# DEVICE_PRM register map
Vendor: Texas Instruments
Peripheral module from a debugger description file (folder omap4460).
Registers are 32-bit, access per field, reset 0x0 unless marked. A register's access mark holds for its fields unless they carry their own. Offsets are as the file gives them; lines under a group give offsets from that group; [hi:lo] are bit positions; {n}, {i} and the like mark numbered series; 'fields as' and 'values as' point back to an identical list; <NAME> marks a mode.

## DEVICE_PRM
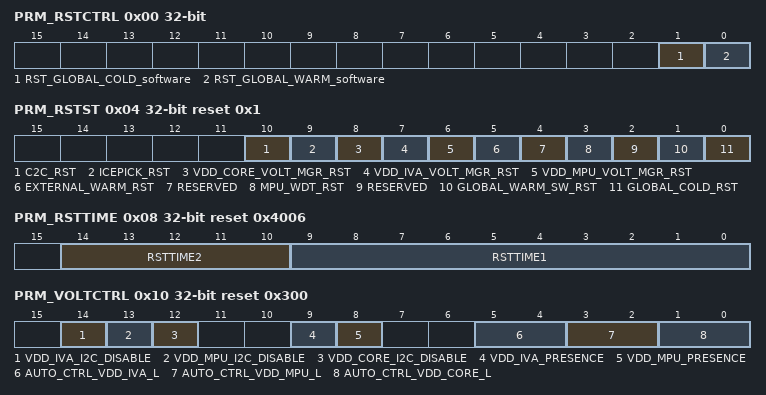
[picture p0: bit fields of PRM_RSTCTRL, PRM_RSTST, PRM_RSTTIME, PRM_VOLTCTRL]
0x00 PRM_RSTCTRL — Global software cold and warm reset control. This register is auto-cleared. Only write 1 is possible. A read returns 0 only.
  [1] RST_GLOBAL_COLD_software rw — Global COLD software reset control. This bit is reset only upon a global cold source of reset.
    0=Global COLD software reset is cleared; 1=Triggers a global COLD software reset. The software must ensure the SDRAM is properly put in sef-refresh mode before applying this reset.
  [0] RST_GLOBAL_WARM_software rw — Global WARM software reset control. This bit is reset upon any global source of reset (warm and cold).
    0=Global warm software reset is cleared; 1=Triggers a global warm software reset
0x04 PRM_RSTST access not given reset 0x1 — This register logs the global reset sources. Each bit is set upon release of the domain reset signal. Must be cleared by software. [warm reset insensitive]
  [10] C2C_RST — C2C warm reset event. This is a source of global warm reset. (access RW W1toClr)
    0=No C2C warm reset; 1=C2C warm reset has occurred
  [9] ICEPICK_RST — IcePick reset event. This is a source of global warm reset initiated by the emulation. (access RW W1toClr)
    0=No ICEPICK reset; 1=IcePick reset has occurred
  [8] VDD_CORE_VOLT_MGR_RST — VDD_CORE voltage manager reset event This is a source of global WARM reset. (access RW W1toClr)
    0=No VDD_CORE voltage manager reset; 1=VDD_CORE voltage manager reset has occurred
  [7] VDD_IVA_VOLT_MGR_RST — VDD_IVA voltage manager reset event This is a source of global WARM reset. (access RW W1toClr)
    0=No VDD_IVA voltage manager reset; 1=VDD_IVA voltage manager reset has occurred
  [6] VDD_MPU_VOLT_MGR_RST — VDD_MPU voltage manager reset event This is a source of global WARM reset. (access RW W1toClr)
    0=No VDD_MPU voltage manager reset; 1=VDD_MPU voltage manager reset has occurred
  [5] EXTERNAL_WARM_RST — External warm reset event (access RW W1toClr)
    0=No global warm reset; 1=Global external warm reset has occurred
  [4] RESERVED — (access RW W1toClr)
  [3] MPU_WDT_RST — MPU Watchdog timer reset event. This is a source of global WARM reset. (access RW W1toClr)
    0=No MPU watchdog reset; 1=MPU wachtdog reset has occurred
  [2] RESERVED — (access RW W1toClr)
  [1] GLOBAL_WARM_SW_RST — Global warm software reset event (access RW W1toClr)
    0=No global warm software reset; 1=Global warm software reset has occurred
  [0] GLOBAL_COLD_RST — Power-on (cold) reset event (access RW W1toClr)
    0=No power-on reset; 1=Power-on reset has occurred
0x08 PRM_RSTTIME reset 0x4006 — Reset duration control. [warm reset insensitive]
  [14:10] RSTTIME2 rw — (Power domain) reset duration 2 (number of RM.SYSCLK clock cycles)
  [9:0] RSTTIME1 rw — (Global) reset duration 1 (number of Func_32k.clk clock cycles)
0x0C PRM_CLKREQCTRL — This register allows controlling the CLKREQ signal towards SCRM.
  [2:0] CLKREQ_COND rw — Control upon which condition CLKREQ signal is de-asserted.
    0=CLKREQ is never de-asserted; 1=CLKREQ is de-asserted when system clock is not required by any function in the device and if all voltage domains are in OFF state; 2=CLKREQ is de-asserted when system clock is not required by any function in the device and if all voltage domains are in RET or OFF state; 3=CLKREQ is de-asserted when system clock is not required by any function in the device and if all voltage domains are in SLEEP or RET or OFF state; 4=CLKREQ is de-asserted when system clock is not required by any function in the device. This is designed for low-power use-cases using the DPLL cascading scheme (ex: MP3); 5=CLKREQ_COND_5_r (Reserved); 6=CLKREQ_COND_6_r (Reserved); 7=CLKREQ_COND_7_r (Reserved)
0x10 PRM_VOLTCTRL reset 0x300 — This register provides voltage domain management controls.
  [14] VDD_IVA_I2C_DISABLE rw — This bit allows disabling I2C interface with powerIC for IVA voltage (for debug purpose only). [warm reset insensitive]
    0=Normal mode: I2C is enabled; 1=Debug mode: I2C is disabled
  [13] VDD_MPU_I2C_DISABLE rw — This bit allows disabling I2C interface with powerIC for MPU voltage (for debug purpose only). [warm reset insensitive]
    0=Normal mode: I2C is enabled; 1=Debug mode: I2C is disabled
  [12] VDD_CORE_I2C_DISABLE rw — This bit allows disabling I2C interface with powerIC for CORE voltage (for debug purpose only). [warm reset insensitive]
    0=Normal mode: I2C is enabled; 1=Debug mode: I2C is disabled
  [9] VDD_IVA_PRESENCE rw — This bit control the presence of IVA voltage in device. [warm reset insensitive]
    0=IVA voltage is not present as an individual voltage: IVA voltage is merged with MPU voltage if VDD_MPU_presence=1. IVA voltage is merged with CORE voltage if VDD_MPU_presence=0.; 1=IVA voltage is present on the device
  [8] VDD_MPU_PRESENCE rw — This bit control the presence of MPU voltage in device. [warm reset insensitive]
    0=MPU voltage is not present as an individual voltage: MPU voltage is merged with IVA voltage if VDD_IVA_presence=1. MPU voltage is merged with CORE voltage if VDD_IVA_presence=0.; 1=MPU voltage is present on the device
  [5:4] AUTO_CTRL_VDD_IVA_L rw — This bit field specifies the state to which the hardware can automatically transition the VDD_IVA_L voltage domain.
    0=Voltage domain transitions are disabled; 1=Voltage domain transitions to SLEEP are enabled; 2=Voltage domain transitions to RET are enabled; 3=AUTO_CTRL_VDD_IVA_L_3_r (reserved)
  [3:2] AUTO_CTRL_VDD_MPU_L rw — This bit field specifies the state to which the hardware can automatically transition the VDD_MPU_L voltage domain.
    0=Voltage domain transitions are disabled; 1=Voltage domain transitions to SLEEP are enabled; 2=Voltage domain transitions to RET are enabled; 3=AUTO_CTRL_VDD_MPU_L_3_r (reserved)
  [1:0] AUTO_CTRL_VDD_CORE_L rw — This bit field specifies the state to which the hardware can automatically transition the VDD_CORE_L voltage domain.
    0=Voltage domain transitions are disabled; 1=Voltage domain transitions to SLEEP are enabled; 2=Voltage domain transitions to RET are enabled; 3=AUTO_CTRL_VDD_CORE_L_3_r (reserved)
0x14 PRM_PWRREQCTRL — This register allows controlling the signal towards power IC.
  [1:0] PWRREQ_COND rw — Control upon which condition from MPU, IVA and CORE voltage domainsPWRREQ is de-asserted.
    0=is never de-asserted; 1=is de-asserted if all voltage domain are in SLEEP, RET or OFF state. Conversely, is asserted upon any voltage domain entering or staying in ON state.; 2=is de-asserted if all voltage domain are in RET or OFF state. Conversely, is asserted upon any voltage domain entering or staying in ON or SLEEP state.; 3=is de-asserted if all voltage domain are in OFF state. Conversely, is asserted upon any voltage domain entering or staying in ON or SLEEP or RET state.
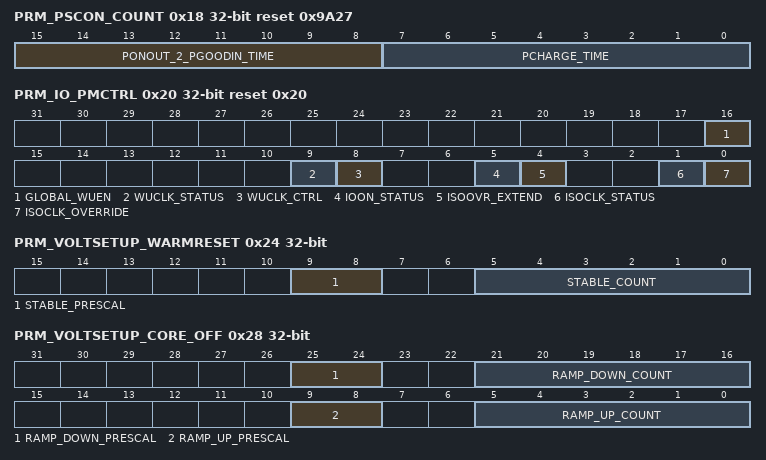
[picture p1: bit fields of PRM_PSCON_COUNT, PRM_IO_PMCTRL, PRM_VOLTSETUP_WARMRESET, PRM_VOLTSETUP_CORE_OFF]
0x18 PRM_PSCON_COUNT reset 0x9A27 — This register allows controlling 2 parameters for power state controller. [warm reset insensitive]
  [15:8] PONOUT_2_PGOODIN_TIME rw — The value 'NbCycles' set in this field determines the duration of the PONOUT to PGOODIN transition for power domain without DPS. The duration is computed as 8 x NbCycles of system clock cycles.
  [7:0] PCHARGE_TIME rw — Number of system clock cycles for the SRAM precharge duration.
0x1C PRM_IO_COUNT reset 0x3A — This register allows controlling LPDDR2 I/O isolation removal setup. [warm reset insensitive]
  [7:0] ISO_2_ON_TIME rw — Determines the setup time of the LPDDR2 IOs going out of isolation. Counting on the system clock. Target is 1.5us.
0x20 PRM_IO_PMCTRL reset 0x20 — This register allows overriding ISOCLK signal towards I/O pad ring.
  [16] GLOBAL_WUEN rw — Global I/O wakeup enable. This is a gating condition to all individual I/O WUEN coming from control module. Gating is done in the Spinner logic.
    0=All individual I/O WUEN are gated in the Spinner logic (overriden to 0); 1=All individual I/O WUEN from control module are going to IOs
  [9] WUCLK_STATUS ro — Gives value of WUCLKOUT signal coming back from I/O pad ring.
  [8] WUCLK_CTRL rw — Direct control on WUCLKIN signal to I/O pad ring.
    0=WUCLKIN signal is driven to 0. I/O wakeup daisy chain is functional as well as I/O whose wakeup feature is enabled.; 1=WUCLKIN signal is driven to 1. I/O wakeup daisy chain is reset and is latching current pad states and WUEN inputs.
  [5] IOON_STATUS ro — Gives the functional status of the I/O ring.
    0=IOON_STATUS_0_r (Part or all of the IOs are not in the ON state, that is are in isolation state); 1=IOON_STATUS_1_r (All IOs are in the ON state)
  [4] ISOOVR_EXTEND rw — Control non-EMIF I/O isolation extension upon a device wakeup from OFF mode.
    0=Non-EMIF I/O isolation is not extended. 'EMIF_ON' I/O transition happens as soon as automatic restore is completed; 1=Non-EMIF I/O isolation is extended. 'EMIF_ON' I/O transition is stalled
  [1] ISOCLK_STATUS ro — Gives value of ISOCLKOUT signal coming back from I/O pad ring.
  [0] ISOCLK_OVERRIDE rw — Override control on ISOCLKIN signal to I/O pad ring. Override should be used at boot time only when it is needed to change the mode of an I/O from 1.8-V default mode to 1.2-V mode. When not overriden, this signal is controlled by hardware only.
    0=ISOCLKIN signal is not overriden; 1=ISOCLKIN signal is overriden to active value (1)
0x24 PRM_VOLTSETUP_WARMRESET — This register provides bit fields for specifying voltage ramp-up and ramp-down times for PRM managed external regulators. These values are used for VDD_CORE_L domain transitions with OFF state. [warm reset insensitive]
  [9:8] STABLE_PRESCAL rw — Determines prescaler for stabilization duration counting.
    0=Ramp-up counter is incremented every 32 system clock cycles; 1=Ramp-up counter is incremented every 256 system clock cycles; 2=Ramp-up counter is incremented every 2048 system clock cycles; 3=Ramp-up counter is incremented every 16384 system clock cycles
  [5:0] STABLE_COUNT rw — Determines the stabilization duration of all VDD_xxx_L regulators upon a global warm reset assertion. The duration is computed according to Stable_Prescal.
0x28 PRM_VOLTSETUP_CORE_OFF — This register provides bit fields for specifying voltage ramp-up and ramp-down times for PRM managed external regulators. These values are used for VDD_CORE_L domain transitions with OFF state. [warm reset insensitive]
  [25:24] RAMP_DOWN_PRESCAL rw — Determines prescaler for ramp-down duration counting.
    0=Ramp-down counter is incremented every 64 system clock cycles; 1=Ramp-down counter is incremented every 256 system clock cycles; 2=Ramp-down counter is incremented every 512 system clock cycles; 3=Ramp-down counter is incremented every 2048 system clock cycles
  [21:16] RAMP_DOWN_COUNT rw — Determines the ramp-down duration of VDD_CORE_L regulators. The duration is computed according to Ramp_Down_Prescal.
  [9:8] RAMP_UP_PRESCAL rw — Determines prescaler for ramp-up duration counting.
    0=Ramp-up counter is incremented every 64 system clock cycles; 1=Ramp-up counter is incremented every 256 system clock cycles; 2=Ramp-up counter is incremented every 512 system clock cycles; 3=Ramp-up counter is incremented every 2048 system clock cycles
  [5:0] RAMP_UP_COUNT rw — Determines the ramp-up duration of VDD_CORE_L regulators. The duration is computed according to Ramp_Up_Prescal. At cold reset, PRCM assumes that VDD_CORE_L will be at a valid ON voltage before SYS_NRESPWRON is de-asserted.
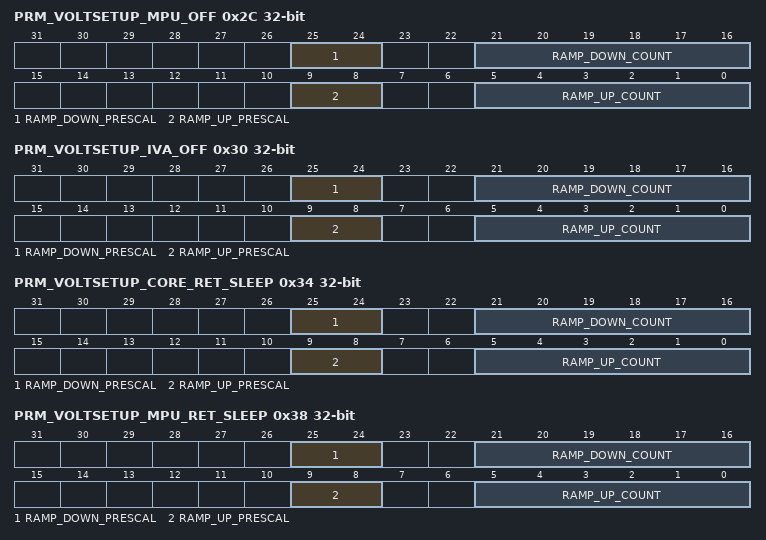
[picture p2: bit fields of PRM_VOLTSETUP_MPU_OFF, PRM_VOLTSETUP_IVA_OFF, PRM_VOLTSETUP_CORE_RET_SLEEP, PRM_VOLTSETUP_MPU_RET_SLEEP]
0x2C PRM_VOLTSETUP_MPU_OFF — This register provides bit fields for specifying voltage ramp-up and ramp-down times for PRM managed external regulators. These values are used for VDD_MPU_L domain transitions to or from OFF state. [warm reset insensitive]
  [25:24] RAMP_DOWN_PRESCAL rw — Determines prescaler for ramp-down duration counting.
    values as PRM_VOLTSETUP_CORE_OFF.RAMP_DOWN_PRESCAL
  [21:16] RAMP_DOWN_COUNT rw — Determines the ramp-down duration of VDD_MPU_L regulators. The duration is computed according to Ramp_Down_Prescal.
  [9:8] RAMP_UP_PRESCAL rw — Determines prescaler for ramp-up duration counting.
    values as PRM_VOLTSETUP_CORE_OFF.RAMP_UP_PRESCAL
  [5:0] RAMP_UP_COUNT rw — Determines the ramp-up duration of VDD_MPU_L regulators. The duration is computed according to Ramp_Up_Prescal. At cold reset, PRCM assumes that VDD_MPU_L will be at a valid ON voltage before SYS_NRESPWRON is de-asserted.
0x30 PRM_VOLTSETUP_IVA_OFF — This register provides bit fields for specifying voltage ramp-up and ramp-down times for PRM managed external regulators. These values are used for VDD_IVA_L domain transitions to or from OFF state. [warm reset insensitive]
  [25:24] RAMP_DOWN_PRESCAL rw — Determines prescaler for ramp-down duration counting.
    values as PRM_VOLTSETUP_CORE_OFF.RAMP_DOWN_PRESCAL
  [21:16] RAMP_DOWN_COUNT rw — Determines the ramp-down duration of VDD_IVA_L regulators. The duration is computed according to Ramp_Down_Prescal.
  [9:8] RAMP_UP_PRESCAL rw — Determines prescaler for ramp-up duration counting.
    values as PRM_VOLTSETUP_CORE_OFF.RAMP_UP_PRESCAL
  [5:0] RAMP_UP_COUNT rw — Determines the ramp-up duration of VDD_IVA_L regulators. The duration is computed according to Ramp_Up_Prescal. At cold reset, PRCM assumes that VDD_IVA_L will be at a valid ON voltage before SYS_NRESPWRON is de-asserted.
0x34 PRM_VOLTSETUP_CORE_RET_SLEEP — This register provides bit fields for specifying voltage ramp-up and ramp-down times for PRM managed external regulators. These values are used for VDD_CORE_L domain transitions between ON and RET or SLEEP state. [warm reset insensitive]
  [25:24] RAMP_DOWN_PRESCAL rw — Determines prescaler for ramp-down duration counting.
    values as PRM_VOLTSETUP_CORE_OFF.RAMP_DOWN_PRESCAL
  [21:16] RAMP_DOWN_COUNT rw — Determines the ramp-down duration of VDD_CORE_L regulators. The duration is computed according to Ramp_Down_Prescal.
  [9:8] RAMP_UP_PRESCAL rw — Determines prescaler for ramp-up duration counting.
    values as PRM_VOLTSETUP_CORE_OFF.RAMP_UP_PRESCAL
  [5:0] RAMP_UP_COUNT rw — Determines the ramp-up duration of VDD_CORE_L regulators. The duration is computed according to Ramp_Up_Prescal.
0x38 PRM_VOLTSETUP_MPU_RET_SLEEP — This register provides bit fields for specifying voltage ramp-up and ramp-down times for PRM managed external regulators. These values are used for VDD_MPU_L domain transitions between ON and RET or SLEEP state. [warm reset insensitive]
  [25:24] RAMP_DOWN_PRESCAL rw — Determines prescaler for ramp-down duration counting.
    values as PRM_VOLTSETUP_CORE_OFF.RAMP_DOWN_PRESCAL
  [21:16] RAMP_DOWN_COUNT rw — Determines the ramp-down duration of VDD_MPU_L regulators. The duration is computed according to Ramp_Down_Prescal.
  [9:8] RAMP_UP_PRESCAL rw — Determines prescaler for ramp-up duration counting.
    0=Ramp-up counter is incremented every 64 system clock cycles; 1=Ramp-up counter is incremented every256 system clock cycles; 2=Ramp-up counter is incremented every 512 system clock cycles; 3=Ramp-up counter is incremented every 2048 system clock cycles
  [5:0] RAMP_UP_COUNT rw — Determines the ramp-up duration of VDD_MPU_L regulators. The duration is computed according to Ramp_Up_Prescal.
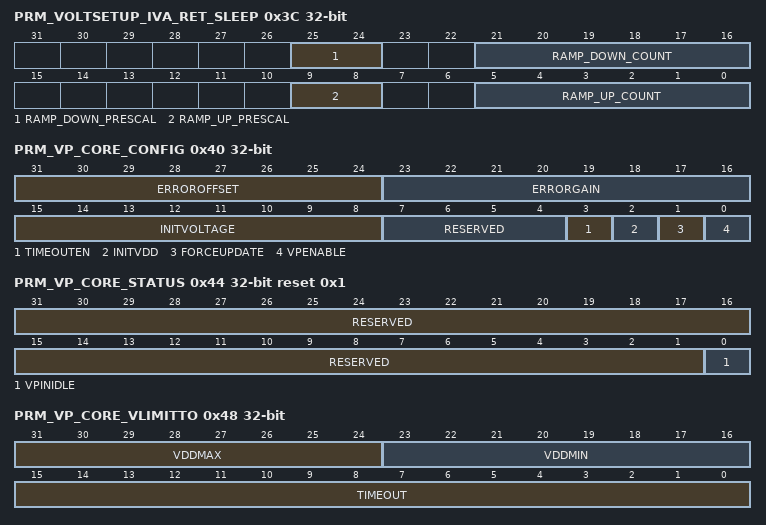
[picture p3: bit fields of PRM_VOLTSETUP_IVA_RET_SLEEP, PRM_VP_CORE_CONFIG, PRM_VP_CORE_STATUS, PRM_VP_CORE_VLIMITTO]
0x3C PRM_VOLTSETUP_IVA_RET_SLEEP — This register provides bit fields for specifying voltage ramp-up and ramp-down times for PRM managed external regulators. These values are used for VDD_IVA_L domain transitions between ON and RET or SLEEP state. [warm reset insensitive]
  [25:24] RAMP_DOWN_PRESCAL rw — Determines prescaler for ramp-down duration counting.
    values as PRM_VOLTSETUP_CORE_OFF.RAMP_DOWN_PRESCAL
  [21:16] RAMP_DOWN_COUNT rw — Determines the ramp-down duration of VDD_IVA_L regulators. The duration is computed according to Ramp_Down_Prescal.
  [9:8] RAMP_UP_PRESCAL rw — Determines prescaler for ramp-up duration counting.
    values as PRM_VOLTSETUP_CORE_OFF.RAMP_UP_PRESCAL
  [5:0] RAMP_UP_COUNT rw — Determines the ramp-up duration of VDD_IVA_L regulators. The duration is computed according to Ramp_Up_Prescal.
0x40 PRM_VP_CORE_CONFIG — This register allows the configuration of the Voltage Processor dedicated to CORE Voltage Domain (VDD_CORE_L).
  [31:24] ERROROFFSET rw — Offset value in the Error to Voltage converter (two's complement number).
  [23:16] ERRORGAIN rw — Gain value in the Error to Voltage converter (two's complement number).
  [15:8] INITVOLTAGE rw — Set the initial voltage level of the SMPS. It must be reconfigured before enable the SmartReflex around a new OPP.
  [7:4] RESERVED ro — Write 0's for future compatibility. Read is undefined.
  [3] TIMEOUTEN rw — Enable or disable the timeout capability of the Voltage Controller State Machine.
    0=Timeout is disabled. Loop will wait indefinitely.; 1=Timeout will occur when TIMEOUT cycles have elapsed
  [2] INITVDD rw — Initializes the voltage in the Voltage Processor.
    0=Reset the initialization bit; 1=The positive edge of InitVdd triggers a write of the value in the InitVoltage into the Voltage Processor
  [1] FORCEUPDATE rw — Forces an update of the SMPS.
    0=Reset the force bit; 1=The positive edge of ForceUpdate triggers an update of the voltage to the SMPS
  [0] VPENABLE rw — Enables or disables the Voltage Processor updates on SR_SInterruptz.
    0=Disables the Voltage Processor; 1=Enables the Voltage Processor
0x44 PRM_VP_CORE_STATUS ro reset 0x1 — This register reflects the idle state of the Voltage Processor dedicated to the CORE Voltage Domain (VDD_CORE_L. This register is read only and automatically updated.
  [31:1] RESERVED — Write 0's for future compatibility. Read is undefined.
  [0] VPINIDLE — CORE Voltage Processor idle status.
    0=VPINIDLE_0_r (The Voltage Processor for CORE is processing. Warm reset sensitive); 1=VPINIDLE_1_r (The Voltage Processor for CORE is in idle state.)
0x48 PRM_VP_CORE_VLIMITTO rw — This register allows the configuration of the voltage limits and timeout values of the Voltage Processor dedicated to the CORE Voltage Domain (VDD_CORE_L).
  [31:24] VDDMAX — Defines the maximum voltage supply level.
  [23:16] VDDMIN — Defines the minimum voltage supply level.
  [15:0] TIMEOUT — Defines Voltage Controller maximum wait time for responses, measured in sysclk cycles.
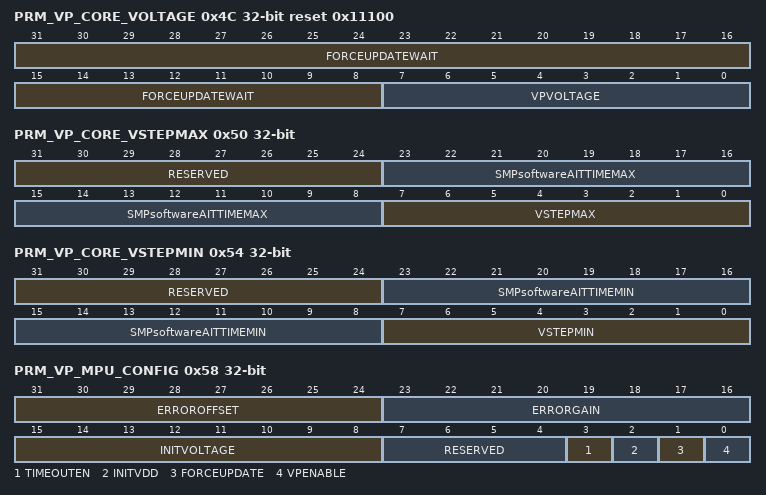
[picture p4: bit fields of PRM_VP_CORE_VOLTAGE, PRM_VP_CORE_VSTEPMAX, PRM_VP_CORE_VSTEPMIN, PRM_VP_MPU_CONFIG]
0x4C PRM_VP_CORE_VOLTAGE reset 0x11100 — This register indicates the current value of the SMPS voltage for the Voltage Processor dedicated to the CORE Voltage Domain (VDD_CORE_L).
  [31:8] FORCEUPDATEWAIT rw — The time voltage processor needs to wait for SMPS to be settled after receiving SMPS acknowledge. This wait only be used during force_update operation.
  [7:0] VPVOLTAGE ro — Indicates the current SMPS programmed voltage.
0x50 PRM_VP_CORE_VSTEPMAX — This register allows the programming of the maximum voltage step and waiting time of the Voltage Processor dedicated to CORE Voltage Domain (VDD_CORE_L).
  [31:24] RESERVED ro — Write 0's for future compatibility. Read is undefined.
  [23:8] SMPsoftwareAITTIMEMAX rw — Slew rate for positive voltage step (in number of cycles per step).
  [7:0] VSTEPMAX rw — Maximum voltage step
0x54 PRM_VP_CORE_VSTEPMIN — This register allows the programming of the minimum voltage step and waiting time of the Voltage Processor dedicated to the CORE Voltage Domain (VDD_CORE_L).
  [31:24] RESERVED ro — Write 0's for future compatibility. Read is undefined.
  [23:8] SMPsoftwareAITTIMEMIN rw — Slew rate for negative voltage step (in number of cycles per step).
  [7:0] VSTEPMIN rw — Minimum voltage step
0x58 PRM_VP_MPU_CONFIG — This register allows the configuration of the Voltage Processor dedicated to MPU Voltage Domain (VDD_MPU_L).
  fields as PRM_VP_CORE_CONFIG
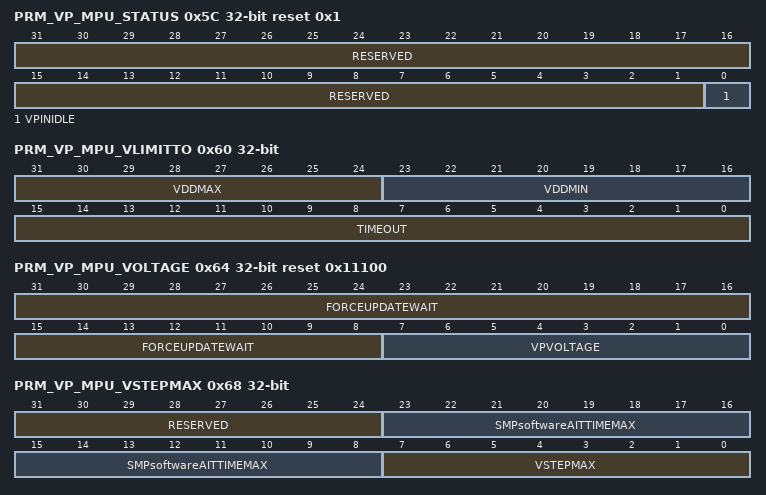
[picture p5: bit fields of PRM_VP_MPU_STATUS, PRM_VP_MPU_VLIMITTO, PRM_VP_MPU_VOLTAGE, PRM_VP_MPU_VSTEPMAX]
0x5C PRM_VP_MPU_STATUS ro reset 0x1 — This register reflects the idle state of the Voltage Processor dedicated to the MPU Voltage Domain (VDD_MPU_L. This register is read only and automatically updated.
  [31:1] RESERVED — Write 0's for future compatibility. Read is undefined.
  [0] VPINIDLE — Voltage Processor 1 idle status.
    0=VPINIDLE_0_r (The Voltage Processor 1 is processing.); 1=VPINIDLE_1_r (The Voltage Processor 1 is in idle state.)
0x60 PRM_VP_MPU_VLIMITTO rw — This register allows the configuration of the voltage limits and timeout values of the Voltage Processor dedicated to the MPU Voltage Domain (VDD_MPU_L).
  fields as PRM_VP_CORE_VLIMITTO
0x64 PRM_VP_MPU_VOLTAGE reset 0x11100 — This register indicates the current value of the SMPS voltage for the Voltage Processor dedicated to the MPU Voltage Domain (VDD_MPU_L).
  fields as PRM_VP_CORE_VOLTAGE
0x68 PRM_VP_MPU_VSTEPMAX — This register allows the programming of the maximum voltage step and waiting time of the Voltage Processor dedicated to MPU Voltage Domain (VDD_MPU_L).
  fields as PRM_VP_CORE_VSTEPMAX
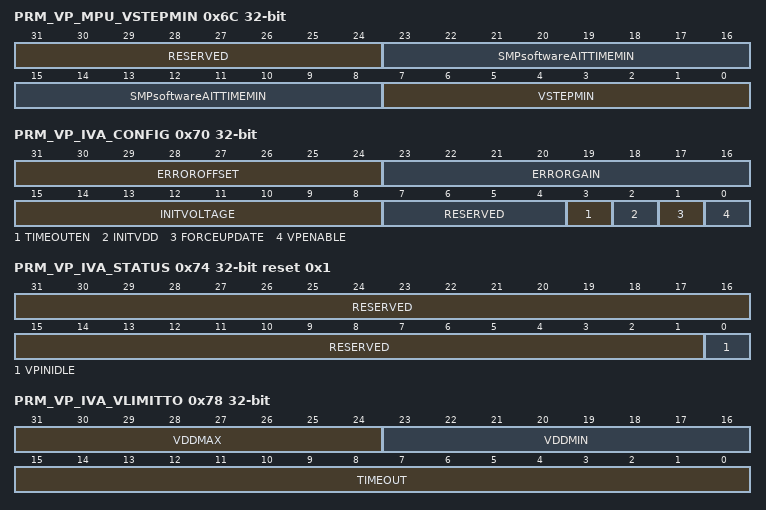
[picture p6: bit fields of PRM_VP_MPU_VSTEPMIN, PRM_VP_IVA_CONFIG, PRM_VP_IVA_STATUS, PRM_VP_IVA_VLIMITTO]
0x6C PRM_VP_MPU_VSTEPMIN — This register allows the programming of the minimum voltage step and waiting time of the Voltage Processor dedicated to the MPU Voltage Domain (VDD_MPU_L).
  fields as PRM_VP_CORE_VSTEPMIN
0x70 PRM_VP_IVA_CONFIG — This register allows the configuration of the Voltage Processor dedicated to IVAVoltage Domain (VDD_IVA_L).
  fields as PRM_VP_CORE_CONFIG
0x74 PRM_VP_IVA_STATUS ro reset 0x1 — This register reflects the idle state of the Voltage Processor dedicated to the MPU Voltage Domain (VDD_IVA_L. This register is read only and automatically updated.
  fields as PRM_VP_MPU_STATUS
0x78 PRM_VP_IVA_VLIMITTO rw — This register allows the configuration of the voltage limits and timeout values of the Voltage Processor dedicated to the IVA Voltage Domain (VDD_IVA_L).
  fields as PRM_VP_CORE_VLIMITTO
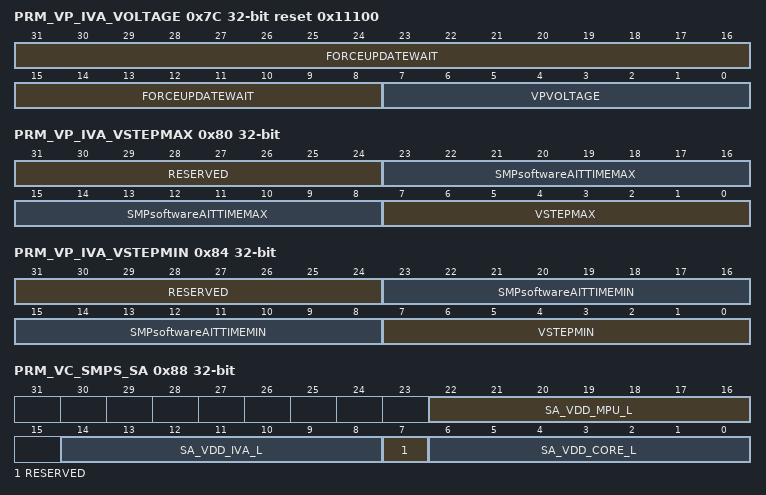
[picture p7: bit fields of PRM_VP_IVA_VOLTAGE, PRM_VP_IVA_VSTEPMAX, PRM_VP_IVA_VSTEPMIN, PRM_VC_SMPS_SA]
0x7C PRM_VP_IVA_VOLTAGE reset 0x11100 — This register indicates the current value of the SMPS voltage for the Voltage Processor dedicated to the IVA Voltage Domain (VDD_IVA_L).
  fields as PRM_VP_CORE_VOLTAGE
0x80 PRM_VP_IVA_VSTEPMAX — This register allows the programming of the maximum voltage step and waiting time of the Voltage Processor dedicated to IVA Voltage Domain (VDD_IVA_L).
  fields as PRM_VP_CORE_VSTEPMAX
0x84 PRM_VP_IVA_VSTEPMIN — This register allows the programming of the minimum voltage step and waiting time of the Voltage Processor dedicated to the IVA Voltage Domain (VDD_IVA_L).
  fields as PRM_VP_CORE_VSTEPMIN
0x88 PRM_VC_SMPS_SA — This register allows the setting of the I2C slave address of the Power IC device. [warm reset insensitive]
  [22:16] SA_VDD_MPU_L rw — Set the I2C slave address value for the third (if any) Power IC device.
  [14:8] SA_VDD_IVA_L rw — Set the I2C slave address value for the second (if any) Power IC device.
  [7] RESERVED ro — Write 0's for future compatibility. Read is undefined.
  [6:0] SA_VDD_CORE_L rw — Set the I2C slave address value for the first Power IC device.
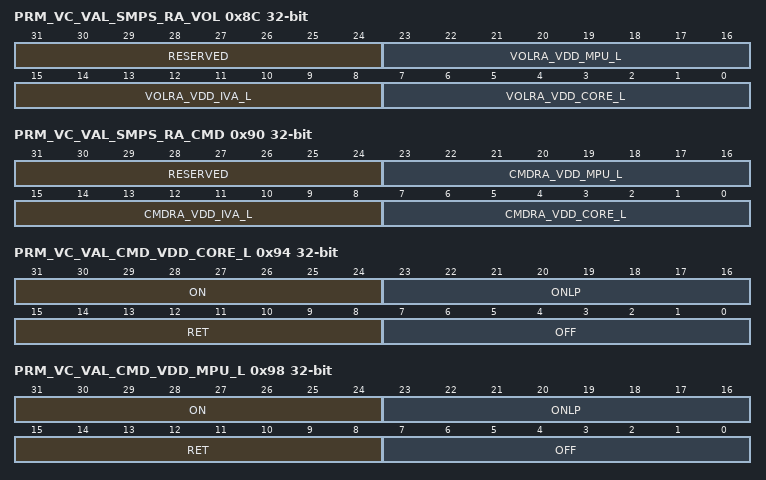
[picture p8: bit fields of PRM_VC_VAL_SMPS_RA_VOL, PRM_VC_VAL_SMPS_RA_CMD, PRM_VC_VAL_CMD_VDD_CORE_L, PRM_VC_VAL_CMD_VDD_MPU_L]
0x8C PRM_VC_VAL_SMPS_RA_VOL — This register allows the setting of the voltage configuration register address for the VDD channels. [warm reset insensitive]
  [31:24] RESERVED ro — Write 0's for future compatibility. Read is undefined.
  [23:16] VOLRA_VDD_MPU_L rw — Voltage configuration register address value for VDD_MPU_L channel
  [15:8] VOLRA_VDD_IVA_L rw — Voltage configuration register address value for VDD_IVA_L channel (if VDD_IVA_L source is placed in same chip as VDD_MPU_L source and have different voltage configuration register)
  [7:0] VOLRA_VDD_CORE_L rw — Voltage configuration register address value for the VDD_CORE_L channel (if VDD_CORE_L source is placed in same chip as VDD_MPU_L source and has different voltage configuration register)
0x90 PRM_VC_VAL_SMPS_RA_CMD — Command (ON/ON-Low-Power/Retention/OFF) configuration register address values for the VDD channels (if used SMPS chips have different command configuration register than voltage configuration register) [warm reset insensitive]
  [31:24] RESERVED ro — Write 0's for future compatibility. Read is undefined.
  [23:16] CMDRA_VDD_MPU_L rw — Command (ON/ON-Low-Power /Retention/OFF) configuration register address value for VDD_MPU_L channel
  [15:8] CMDRA_VDD_IVA_L rw — Command (ON/ON-Low-Power /Retention/OFF) configuration register address value for VDD_IVA_L channel (if VDD_IVA_L source has different command configuration register than voltage VDD_MPU_L)
  [7:0] CMDRA_VDD_CORE_L rw — Command (ON/ON-Low-Power /Retention/OFF) configuration register address value for VDD_CORE_L channel (if VDD_CORE_L source has different command configuration register than voltage VDD_MPU_L)
0x94 PRM_VC_VAL_CMD_VDD_CORE_L rw — This register allows the setting of the ON/ON-Low-Power/Retention/OFF command values for VDD_CORE_L channel. [warm reset insensitive]
  [31:24] ON — Set the ON command value.
  [23:16] ONLP — Set the ON-Low-Power command value.
  [15:8] RET — Set the RET command value.
  [7:0] OFF — Set the OFF command value.
0x98 PRM_VC_VAL_CMD_VDD_MPU_L rw — This register allows the setting of the ON/ON-Low-Power/Retention/OFF command values for VDD_MPU_L channel. [warm reset insensitive]
  fields as PRM_VC_VAL_CMD_VDD_CORE_L
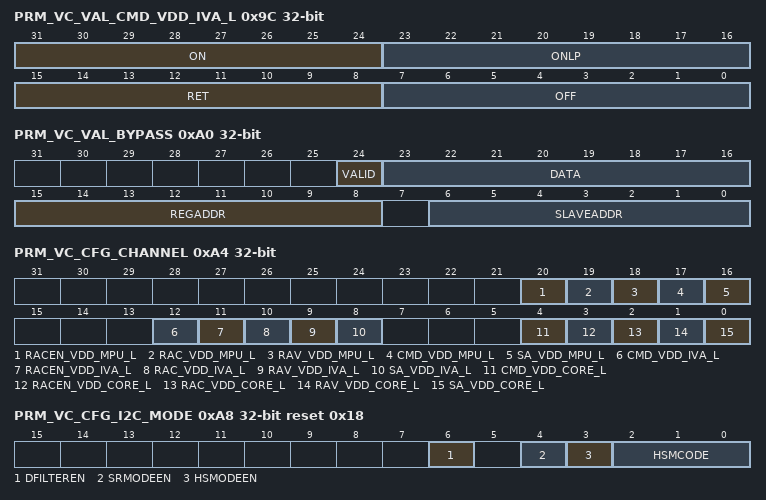
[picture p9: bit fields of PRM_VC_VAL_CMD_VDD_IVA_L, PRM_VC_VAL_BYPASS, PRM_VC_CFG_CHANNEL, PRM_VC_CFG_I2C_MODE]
0x9C PRM_VC_VAL_CMD_VDD_IVA_L rw — This register allows the setting of the ON/ON-Low-Power/Retention/OFF command values for VDD_IVA_L channel. [warm reset insensitive]
  fields as PRM_VC_VAL_CMD_VDD_CORE_L
0xA0 PRM_VC_VAL_BYPASS access not given — Bypass data values register used for bypass command channel to send other configuration information (other then voltage configuration parameters) for SMPS chips which have no other configuration interface then this I2C interface. [warm reset insensitive]
  [24] VALID — This bit validates the bypass command. It is automatically cleared by hardware either after getting the acknowledge back from the SMPS or if an error occured. (access RW WSpecial)
    0=VALID_0_r (The last command send has been acknowledged); 1=Pending command is being process
  [23:16] DATA rw — Data to send to the Power IC device.
  [15:8] REGADDR rw — Set the address of Power IC device register to configure.
  [6:0] SLAVEADDR rw — Set the I2C slave address value.
0xA4 PRM_VC_CFG_CHANNEL — This register allows the configuration pointers for both VDD channels. [warm reset insensitive]
  [20] RACEN_VDD_MPU_L rw — Enable bit for usage of RAC_VDD_MPU_L
    0=VDD_MPU_L channel uses VOLRA values for register address of VFSM-s commands. VFSM-s commands goes also to voltage configuration register.; 1=VDD_MPU_L channel uses CMDRA values for register address of VFSM-s commands. VFSM-s commands goes to different command configuration register.
  [19] RAC_VDD_MPU_L rw — Command (ON/ON-Low-Power/Retention/OFF) configuration register address pointer for VDD_MPU_L channel. (This bit has no influence on the VDD_MPU_L channel.)
    0=Select CMDRA_VDD_CORE_L for VDD_MPU_L channel; 1=Select CMDRA_VDD_MPU_L for VDD_MPU_L channel
  [18] RAV_VDD_MPU_L rw — Voltage configuration register address pointer for VDD_MPU_L channel. (This bit has no influence on the VDD_MPU_L channel.)
    0=Select VOLRA_VDD_CORE_L for VDD_MPU_L channel; 1=Select VOLRA_VDD_MPU_L for VDD_MPU_L channel
  [17] CMD_VDD_MPU_L rw — Command values (ON/ON-Low-Power/Retention/OFF voltage values) set selection for VDD_MPU_L channel. (This bit has no influence on the VDD_MPU_L channel.)
    0=VDD_MPU_L channel use VC_VAL_CMD_VDD_CORE_L set for command values; 1=VDD_MPU_L channel use VC_VAL_CMD_VDD_MPU_L set for command values
  [16] SA_VDD_MPU_L rw — Slave address pointer for VDD_MPU_L channel. (This bit has no influence on the VDD_MPU_L channel.)
    0=Select SA_VDD_CORE_L for VDD_MPU_L channel; 1=Select SA_VDD_MPU_L for VDD_MPU_L channel
  [12] CMD_VDD_IVA_L rw — Command values (ON/ON-Low-Power/Retention/OFF voltage values) set selection for VDD_IVA_L channel
    0=VDD_IVA_L channel use VC_VAL_CMD_VDD_MPU_L set for command values; 1=VDD_IVA_L channel use VC_VAL_CMD_VDD_IVA_L set for command values
  [11] RACEN_VDD_IVA_L rw — Enable bit for usage of RAC_VDD_IVA_L
    0=VDD_IVA_L channel uses VOLRA values for register address of VFSM-s commands. VFSM-s commands goes also to voltage configuration register.; 1=VDD_IVA_L channel uses CMDRA values for register address of VFSM-s commands. VFSM-s commands goes to different command configuration register.
  [10] RAC_VDD_IVA_L rw — Command (ON/ON-Low-Power/Retention/OFF) configuration register address pointer for VDD_IVA_L channel
    0=Select CMDRA_VDD_MPU_L for VDD_IVA_L channel; 1=Select CMDRA_VDD_IVA_L for VDD_IVA_L channel
  [9] RAV_VDD_IVA_L rw — Voltage configuration register address pointer for VDD_IVA_L channel.
    0=Select VOLRA_VDD_MPU_L for VDD_IVA_L channel; 1=Select VOLRA_VDD_IVA_L for VDD_IVA_L channel
  [8] SA_VDD_IVA_L rw — Slave address pointer for VDD_IVA_L channel.
    0=Select SA_VDD_MPU_L for VDD_IVA_L channel; 1=Select SA_VDD_IVA_L for VDD_IVA_L channel
  [4] CMD_VDD_CORE_L rw — Command values (ON/ON-Low-Power/Retention/OFF voltage values) set selection for VDD_CORE_L channel
  [3] RACEN_VDD_CORE_L rw — Enable bit for usage of RAC_VDD_CORE_L.
    0=VDD_CORE_L channel use VOLRA values for register address of VFSM-s commands. VFSM-s commands goes also to voltage configuration register.; 1=VDD_CORE_L channel use CMDRA values for register address of VFSM-s commands. VFSM-s commands goes to different command configuration register.
  [2] RAC_VDD_CORE_L rw — Command (ON/ON-Low-Power/Retention/OFF) configuration register address pointer for VDD_CORE_L channel.
    0=Select CMDRA_VDD_MPU_L for the VDD_CORE_L channel; 1=Select CMDRA_VDD_CORE_L for the VDD_CORE_L channel
  [1] RAV_VDD_CORE_L rw — Voltage configuration register address pointer for VDD_CORE_L channel.
    0=Select VOLRA_VDD_MPU_L for the VDD_CORE_L channel; 1=Select VOLRA_VDD_CORE_L for the VDD_CORE_L channel
  [0] SA_VDD_CORE_L rw — Slave address pointer for VDD_CORE_L channel.
    0=Select SA_VDD_MPU_L for the VDD_CORE_L channel; 1=Select SA_VDD_CORE_L for the VDD_CORE_L channel
0xA8 PRM_VC_CFG_I2C_MODE reset 0x18 — I2C configuration register. [warm reset insensitive]
  [6] DFILTEREN rw — This field enables double filter procedure for IC input lines
    0=I2C bus digital filter rejects all glitches smaller than 1 sytem clock cycle; 1=I2C bus digital filter rejects all glitches smaller than 2 sytem clock cycles
  [4] SRMODEEN rw — Enables the IC repeated start operation mode.(Effect of holding the SCL and SDA lines low, in effect blocking the I2C bus from losing arbitration between repeated start points). . Use of this feature results from a trade-off between speed and power consumption of I2C interface. .
    0=Disables the repeated start operation mode; 1=Enables the repeated start operation mode
  [3] HSMODEEN rw — Enables IC bus high-speed mode.
    0=Disables the I2C high-speed mode; 1=Enables the I2C high-speed mode
  [2:0] HSMCODE rw — Master code value for IC high-speed preamble transmission.
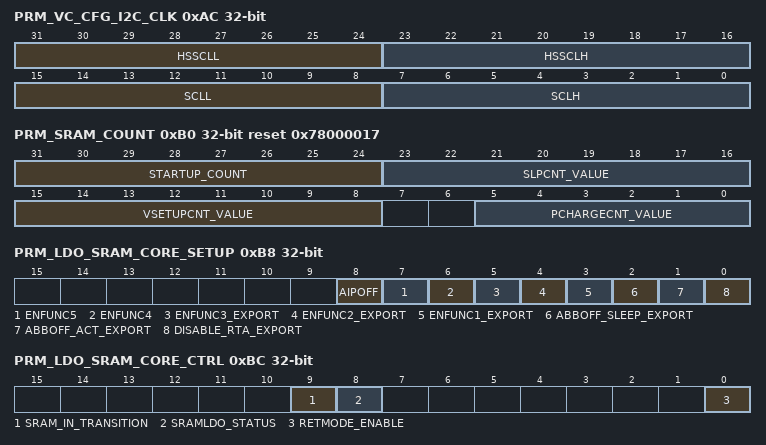
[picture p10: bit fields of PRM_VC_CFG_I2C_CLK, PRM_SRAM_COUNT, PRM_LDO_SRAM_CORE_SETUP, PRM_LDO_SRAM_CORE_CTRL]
0xAC PRM_VC_CFG_I2C_CLK rw — I2C Interface clock configuration parameters. [warm reset insensitive]
  [31:24] HSSCLL — Number of the system clock cycles, necessary to count the low period of the I2C clock signal, when the I2C interface runs in high-speed mode of operation. The value of the bit field is automatically increased by 7.
  [23:16] HSSCLH — Number of the system clock cycles, necessary to count the high period of the I2C clock signal, when the I2C interface runs in high-speed mode of operation. The value of the bit field is automatically increased by 5.
  [15:8] SCLL — Number of the system clock cycles, necessary to count the low period of the I2C clock signal, when the I2C interface runs in fast mode of operation. The value of the bit field is automatically increased by 7.
  [7:0] SCLH — Number of the system clock cycles, necessary to count the high period of the I2C clock signal, when the I2C interface runs in fast mode of operation. The value of the bit field is automatically increased by 5.
0xB0 PRM_SRAM_COUNT reset 0x78000017 — Common setup for SRAM LDO transition counters. Applies to all voltage domains. [warm reset insensitive]
  [31:24] STARTUP_COUNT rw — Determines the start-up duration of SRAM and ABB LDO. The duration is computed as 16 x NbCycles of system clock cycles. Target is 50us.
  [23:16] SLPCNT_VALUE rw — Delay between retention/off assertion of last SRAM bank and SRAMALLRET signal to LDO is driven high. Counting on system clock. Target is 2us.
  [15:8] VSETUPCNT_VALUE rw — SRAM LDO rampup time from retention to active mode. The duration is computed as 8 x NbCycles of system clock cycles. Target is 30us.
  [5:0] PCHARGECNT_VALUE rw — Delay between de-assertion of standby_rta_ret_on and standby_rta_ret_good. Counting on system clock. Target is 600ns.
0xB4 PRM_SRAM_WKUP_SETUP access not given — Setup of memory in WKUP voltage domain. [warm reset insensitive]
  [0] DISABLE_RTA_EXPORT — Control for HD memory RTA feature. After PowerOn reset and Efuse sensing, this bit field is automatically loaded with an Efuse value from control module. Bit field remains writable after this. (access RW WSpecial)
    0=HD memory RTA feature is enabled; 1=HD memory RTA feature is disabled
0xB8 PRM_LDO_SRAM_CORE_SETUP access not given — Setup of the SRAM LDO for CORE voltage domain. [warm reset insensitive]
  [8] AIPOFF rw — Override on AIPOFF input of SRAM LDO.
    0=AIPOFF signal is not overriden; 1=AIPOFF signal is overriden to 1. Corresponding SRAM LDO is disabled and in HZ mode.
  [7] ENFUNC5 rw — ENFUNC5 input of SRAM LDO.
    0=Active to retention is a one step transfer; 1=Active to retention is a two steps transfer
  [6] ENFUNC4 rw — ENFUNC4 input of SRAM LDO.
    0=One external clock is supplied; 1=No external clock is supplied
  [5] ENFUNC3_EXPORT — ENFUNC3 input of SRAM LDO. After PowerOn reset and Efuse sensing, this bit field is automatically loaded with an Efuse value from control module. Bit field remains writable after this. (access RW WSpecial)
    0=Sub regulation is disabled; 1=Sub regulation is enabled
  [4] ENFUNC2_EXPORT — ENFUNC2 input of SRAM LDO. After PowerOn reset and Efuse sensing, this bit field is automatically loaded with an Efuse value from control module. Bit field remains writable after this. (access RW WSpecial)
    0=External cap is used; 1=External cap is not used
  [3] ENFUNC1_EXPORT — ENFUNC1 input of SRAM LDO. After PowerOn reset and Efuse sensing, this bit field is automatically loaded with an Efuse value from control module. Bit field remains writable after this. (access RW WSpecial)
    0=Short circuit protection is disabled; 1=Short circuit protection is enabled
  [2] ABBOFF_SLEEP_EXPORT — Determines whether SRAMNWA is supplied by VDDS or VDDAR during deep-sleep. After PowerOn reset and Efuse sensing, this bit field is automatically loaded with an Efuse value from control module. Bit field remains writable after this. (access RW WSpecial)
    0=SRAMNWA supplied with VDDS; 1=SRAMNWA supplied with VDDAR
  [1] ABBOFF_ACT_EXPORT — Determines whether SRAMNWA is supplied by VDDS or VDDAR during active mode. After PowerOn reset and Efuse sensing, this bit field is automatically loaded with an Efuse value from control module. Bit field remains writable after this. (access RW WSpecial)
    0=SRAMNWA supplied with VDDS; 1=SRAMNWA supplied with VDDAR
  [0] DISABLE_RTA_EXPORT — Control for HD memory RTA feature. After PowerOn reset and Efuse sensing, this bit field is automatically loaded with an Efuse value from control module. Bit field remains writable after this. (access RW WSpecial)
    values as PRM_SRAM_WKUP_SETUP.DISABLE_RTA_EXPORT
0xBC PRM_LDO_SRAM_CORE_CTRL — Control and status of the SRAM LDO for CORE voltage domain. [warm reset insensitive]
  [9] SRAM_IN_TRANSITION ro — Status indicating SRAM LDO state machine state.
    0=SRAM_IN_TRANSITION_0_r (SRAM LDO state machine is stable); 1=SRAM_IN_TRANSITION_1_r (SRAM LDO state machine is in transition state)
  [8] SRAMLDO_STATUS ro
    0=SRAMLDO_STATUS_0_r (SRAMLDO is in ACTIVE mode.); 1=SRAMLDO_STATUS_1_r (SRAMLDO is on RETENTION mode.)
  [0] RETMODE_ENABLE rw — Control if the SRAM LDO retention mode is used or not.
    0=SRAM LDO is not allowed to go to RET mode; 1=SRAM LDO go to RET mode when all memory of voltage domain are OFF or RET
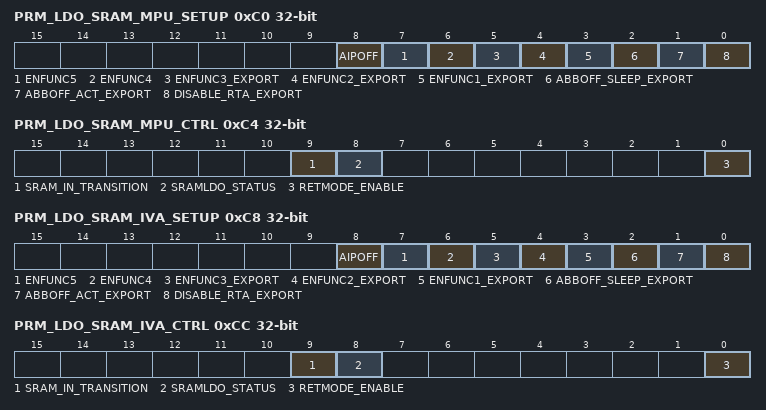
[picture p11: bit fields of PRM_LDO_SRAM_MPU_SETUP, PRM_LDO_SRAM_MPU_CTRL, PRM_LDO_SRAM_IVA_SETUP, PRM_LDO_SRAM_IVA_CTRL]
0xC0 PRM_LDO_SRAM_MPU_SETUP access not given — Setup of the SRAM LDO for MPU voltage domain. [warm reset insensitive]
  [8] AIPOFF rw — Override on AIPOFF input of SRAM LDO.
    values as PRM_LDO_SRAM_CORE_SETUP.AIPOFF
  [7] ENFUNC5 rw — ENFUNC5 input of SRAM LDO.
    values as PRM_LDO_SRAM_CORE_SETUP.ENFUNC5
  [6] ENFUNC4 rw — ENFUNC4 input of SRAM LDO.
    values as PRM_LDO_SRAM_CORE_SETUP.ENFUNC4
  [5] ENFUNC3_EXPORT rw — ENFUNC3 input of SRAM LDO. After PowerOn reset and Efuse sensing, this bit field is automatically loaded with an Efuse value from control module. Bit field remains writable after this.
    0=Sub regulation is disabled; 1=Sub regulation is enabled
  [4] ENFUNC2_EXPORT — ENFUNC2 input of SRAM LDO. After PowerOn reset and Efuse sensing, this bit field is automatically loaded with an Efuse value from control module. Bit field remains writable after this. (access RW WSpecial)
    0=External cap is used; 1=External cap is not used
  [3] ENFUNC1_EXPORT rw — ENFUNC1 input of SRAM LDO. After PowerOn reset and Efuse sensing, this bit field is automatically loaded with an Efuse value from control module. Bit field remains writable after this.
    values as PRM_LDO_SRAM_CORE_SETUP.ENFUNC1_EXPORT
  [2] ABBOFF_SLEEP_EXPORT — Determines whether SRAMNWA is supplied by VDDS or VDDAR during deep-sleep. After PowerOn reset and Efuse sensing, this bit field is automatically loaded with an Efuse value from control module. Bit field remains writable after this. (access RW WSpecial)
    0=SRAMNWA supplied with VDDS; 1=SRAMNWA supplied with VDDAR
  [1] ABBOFF_ACT_EXPORT — Determines whether SRAMNWA is supplied by VDDS or VDDAR during active mode. After PowerOn reset and Efuse sensing, this bit field is automatically loaded with an Efuse value from control module. Bit field remains writable after this. (access RW WSpecial)
    0=SRAMNWA supplied with VDDS; 1=SRAMNWA supplied with VDDAR
  [0] DISABLE_RTA_EXPORT — Control for HD memory RTA feature. After PowerOn reset and Efuse sensing, this bit field is automatically loaded with an Efuse value from control module. Bit field remains writable after this. (access RW WSpecial)
    values as PRM_SRAM_WKUP_SETUP.DISABLE_RTA_EXPORT
0xC4 PRM_LDO_SRAM_MPU_CTRL — Control and status of the SRAM LDO for MPU voltage domain. [warm reset insensitive]
  fields as PRM_LDO_SRAM_CORE_CTRL
0xC8 PRM_LDO_SRAM_IVA_SETUP access not given — Setup of the SRAM LDO for IVA voltage domain. [warm reset insensitive]
  fields as PRM_LDO_SRAM_MPU_SETUP
0xCC PRM_LDO_SRAM_IVA_CTRL — Control and status of the SRAM LDO for IVA voltage domain. [warm reset insensitive]
  fields as PRM_LDO_SRAM_CORE_CTRL
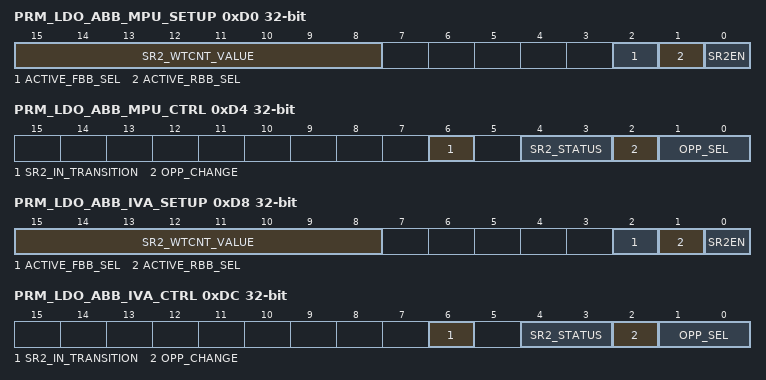
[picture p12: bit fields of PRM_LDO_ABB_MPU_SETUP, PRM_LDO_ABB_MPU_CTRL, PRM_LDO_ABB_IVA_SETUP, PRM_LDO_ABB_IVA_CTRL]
0xD0 PRM_LDO_ABB_MPU_SETUP — Selects the MPU_ABB LDO mode.
  [15:8] SR2_WTCNT_VALUE rw — LDO settling time for active-mode OPP change. Counting at a 16 system clock cycles rate. Target is 50us. [warm reset insensitive]
  [2] ACTIVE_FBB_SEL rw — Defines ABB LDO mode when voltage is in slow fast OPP. [warm reset insensitive]
    0=ABB LDO is in bypass mode; 1=ABB LDO is in ABB Set1 mode
  [1] ACTIVE_RBB_SEL rw — Defines ABB LDO mode when MPU voltage is in OPP_TURBO. [warm reset insensitive]
    0=ABB LDO is in bypass mode; 1=ABB LDO is in ABB Set2 mode
  [0] SR2EN rw — Enable ABB power management
    0=ABB LDO is put in bypass mode; 1=ABB LDO will operate accordingly to settings
0xD4 PRM_LDO_ABB_MPU_CTRL access not given — Control and Status of ABB on MPU voltage domain. [warm reset insensitive]
  [6] SR2_IN_TRANSITION ro — Indicates VBBLDO_CON is or is not in transition state. This output should be used by programming interface to clear OPP_CHANGE bit as an indication of OPP change completion.
    0=SR2_IN_TRANSITION_0_r; 1=SR2_IN_TRANSITION_1_r (Indicates that VBBLDO_CON is in transition and SR2_STATUS bits are not stable to read.)
  [4:3] SR2_STATUS ro — Indicate ABB LDO current operation status
    0=SR2_STATUS_0_r (ABB LDO is placed in bypass mode.); 1=SR2_STATUS_1_r (ABB LDO is placed in ABB Set2 active mode); 2=SR2_STATUS_2_r (ABB LDO is placed in ABB Set1 active mode.); 3=SR2_STATUS_3_r (Reserved)
  [2] OPP_CHANGE — When OPP_CHANGE is set to 1, VBBLDO_CON samples OPP_SEL and ACTIVE_FBB_SEL/ACTIVE_RBB_SEL upon detecting rising edge. VBBLDO_CON asserts signal SR2_IN_TRANSITION in response to OPP_CHANGE. OPP_CHANGE should be cleared to 0 when SR2_IN_TRANSITION from VBBLDO_CON is de-asserted. (access RW WSpecial)
  [1:0] OPP_SEL rw — Selects the OPP at which the MPU voltage domain is operating
    0=default : Nominal; 1=Fast OPP; 2=Nominal; 3=Slow OPP
0xD8 PRM_LDO_ABB_IVA_SETUP — Selects the IVA_ABB LDO mode.
  [15:8] SR2_WTCNT_VALUE rw — LDO settling time for active-mode OPP change. Counting at a 16 system clock cycles rate. Target is 50us. [warm reset insensitive]
  [2] ACTIVE_FBB_SEL rw — Defines ABB LDO mode when voltage is in slow fast OPP. [warm reset insensitive]
    0=ABB LDO is in bypass mode; 1=ABB LDO is in ABB Set1 mode
  [1] ACTIVE_RBB_SEL rw — Defines ABB LDO mode when IVA voltage is in OPP_TURBO. [warm reset insensitive]
    0=ABB LDO is in bypass mode; 1=ABB LDO is in ABB Set2 mode
  [0] SR2EN rw — Enable ABB power management
    values as PRM_LDO_ABB_MPU_SETUP.SR2EN
0xDC PRM_LDO_ABB_IVA_CTRL access not given — Control and Status of ABB on IVA voltage domain. [warm reset insensitive]
  [6] SR2_IN_TRANSITION ro — Indicates VBBLDO_CON is or is not in transition state. This output should be used by programming interface to clear OPP_CHANGE bit as an indication of OPP change completion.
    values as PRM_LDO_ABB_MPU_CTRL.SR2_IN_TRANSITION
  [4:3] SR2_STATUS ro — Indicate ABB LDO current operation status
    values as PRM_LDO_ABB_MPU_CTRL.SR2_STATUS
  [2] OPP_CHANGE — When OPP_CHANGE is set to 1, VBBLDO_CON samples OPP_SEL and ACTIVE_FBB_SEL/ACTIVE_RBB_SEL upon detecting rising edge. VBBLDO_CON asserts signal SR2_IN_TRANSITION in response to OPP_CHANGE. OPP_CHANGE should be cleared to 0 when SR2_IN_TRANSITION from VBBLDO_CON is de-asserted. (access RW WSpecial)
  [1:0] OPP_SEL rw — Selects the OPP at which the IVA voltage domain is operating (Fast OPP, Nominal OPP or Slow OPP)
    0=default : Nominal; 1=Fast OPP; 2=Nominal; 3=Slow OPP
0xE0 PRM_LDO_BANDGAP_SETUP reset 0x78 — Control of the bandgap. [warm reset insensitive]
  [7:0] STARTUP_COUNT rw — Determines the start-up duration of BANDGAP. The duration is computed as 32 x NbCycles of system clock cycles. Target is 100us.
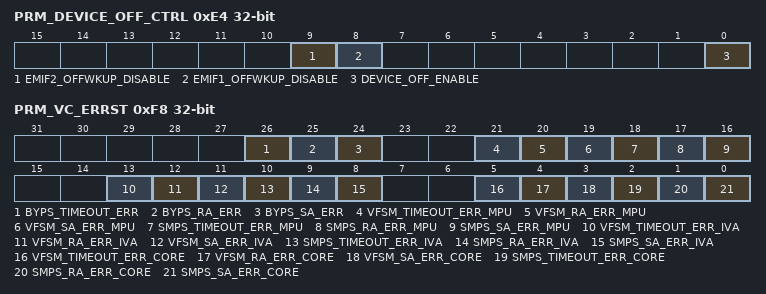
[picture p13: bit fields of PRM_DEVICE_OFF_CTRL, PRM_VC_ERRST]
0xE4 PRM_DEVICE_OFF_CTRL — This register is used to control device OFF transition.
  [9] EMIF2_OFFWKUP_DISABLE rw — Controls the EMIF2_DEVICE_OFFWKUP_CORESRTACTST notifier sent to EMIF2 upon a device wakeup from off mode. (Warm reset insensitive)
    0=Notifier is activated; 1=Notifier is not activated – stays low
  [8] EMIF1_OFFWKUP_DISABLE rw — Controls the EMIF1_DEVICE_OFFWKUP_CORESRTACTST notifier sent to EMIF1 upon a device wakeup from off mode. (Warm reset insensitive)
    values as EMIF2_OFFWKUP_DISABLE
  [0] DEVICE_OFF_ENABLE rw — Controls transition to device OFF mode.
    0=Device is not allowed to perform transition to off mode; 1=Device is allowed to perform transition to off mode as soon as all power domains in MPU, IVA and CORE voltage are in OFF or OsoftwareRET state (open switch retention)
0xE8 PRM_PHASE1_CNDP access not given reset 0x4A05E000 — This register stores the start descriptor address of automatic restore phase1. [warm reset insensitive]
  [31:0] PHASE1_CNDP — Start descriptor address of automatic restore phase1. Hard-coded to SAR_ROM base address. (access R Rreturns)
0xEC PRM_PHASE2A_CNDP access not given reset 0x4A05E030 — This register stores the start descriptor address of automatic restore phase2A. [warm reset insensitive]
  [31:0] PHASE2A_CNDP — Start descriptor address of automatic restore phase2A. Hard-coded to SAR_ROM base address + 0x30. (access R Rreturns)
0xF0 PRM_PHASE2B_CNDP access not given reset 0x4A05E060 — This register stores the start descriptor address of automatic restore phase2B. [warm reset insensitive]
  [31:0] PHASE2B_CNDP — Start descriptor address of automatic restore phase2B. Hard-coded to SAR_ROM base address + 0x60. (access R Rreturns)
0xF8 PRM_VC_ERRST access not given — This debug register logs the error status coming from Voltage Controller. Must be cleared by software.
  [all] fields
    0=No error; 1=An error has been logged
  [26] BYPS_TIMEOUT_ERR — Bypass command frame is finished but is not acknowledged by the slave, or (I2C multimaster) arbitration lost. (access RW W1toClr)
  [25] BYPS_RA_ERR — Wrong register address error for bypass command (access RW W1toClr)
  [24] BYPS_SA_ERR — Wrong slave address error for bypass command (access RW W1toClr)
  [21] VFSM_TIMEOUT_ERR_MPU — MPU voltage FSM command frame is finished but is not acknowledged by the slave, or (I2C multimaster) arbitration lost. (access RW W1toClr)
  [20] VFSM_RA_ERR_MPU — Wrong register address error for MPU voltage FSM (access RW W1toClr)
  [19] VFSM_SA_ERR_MPU — Wrong slave address error for MPU voltage FSM (access RW W1toClr)
  [18] SMPS_TIMEOUT_ERR_MPU — MPU voltage processor command frame is finished but is not acknowledged by the slave, or (I2C multimaster) arbitration lost. (access RW W1toClr)
  [17] SMPS_RA_ERR_MPU — Wrong register address error for MPU voltage processor (access RW W1toClr)
  [16] SMPS_SA_ERR_MPU — Wrong slave address error for MPU voltage processor (access RW W1toClr)
  [13] VFSM_TIMEOUT_ERR_IVA — IVA voltage FSM command frame is finished but is not acknowledged by the slave, or (I2C multimaster) arbitration lost. (access RW W1toClr)
  [12] VFSM_RA_ERR_IVA — Wrong register address error for IVA voltage FSM (access RW W1toClr)
  [11] VFSM_SA_ERR_IVA — Wrong slave address error for IVA voltage FSM (access RW W1toClr)
  [10] SMPS_TIMEOUT_ERR_IVA — IVA voltage processor command frame is finished but is not acknowledged by the slave, or (I2C multimaster) arbitration lost. (access RW W1toClr)
  [9] SMPS_RA_ERR_IVA — Wrong register address error for IVA voltage processor (access RW W1toClr)
  [8] SMPS_SA_ERR_IVA — Wrong slave address error for IVA voltage processor (access RW W1toClr)
  [5] VFSM_TIMEOUT_ERR_CORE — CORE voltage FSM command frame is finished but is not acknowledged by the slave, or (I2C multimaster) arbitration lost. (access RW W1toClr)
  [4] VFSM_RA_ERR_CORE — Wrong register address error for CORE voltage FSM (access RW W1toClr)
  [3] VFSM_SA_ERR_CORE — Wrong slave address error for CORE voltage FSM (access RW W1toClr)
  [2] SMPS_TIMEOUT_ERR_CORE — CORE voltage processor command frame is finished but is not acknowledged by the slave, or (I2C multimaster) arbitration lost. (access RW W1toClr)
  [1] SMPS_RA_ERR_CORE — Wrong register address error for CORE voltage processor (access RW W1toClr)
  [0] SMPS_SA_ERR_CORE — Wrong slave address error for CORE voltage processor (access RW W1toClr)
